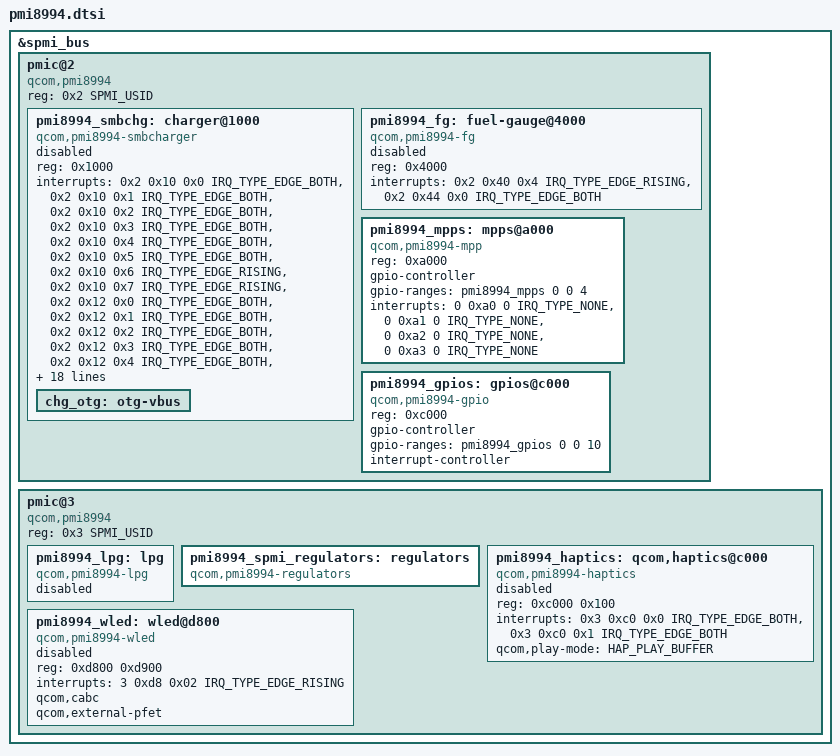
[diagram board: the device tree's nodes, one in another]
// SPDX-License-Identifier: GPL-2.0
#include <dt-bindings/interrupt-controller/irq.h>
#include <dt-bindings/spmi/spmi.h>
#include <dt-bindings/input/qcom,spmi-haptics.h>

&spmi_bus {

	pmic@2 {
		compatible = "qcom,pmi8994", "qcom,spmi-pmic";
		reg = <0x2 SPMI_USID>;
		#address-cells = <1>;
		#size-cells = <0>;

		pmi8994_smbchg: charger@1000 {
			compatible = "qcom,pmi8994-smbcharger";
			reg = <0x1000>;

			interrupts = <0x2 0x10 0x0 IRQ_TYPE_EDGE_BOTH>,
				     <0x2 0x10 0x1 IRQ_TYPE_EDGE_BOTH>,
				     <0x2 0x10 0x2 IRQ_TYPE_EDGE_BOTH>,
				     <0x2 0x10 0x3 IRQ_TYPE_EDGE_BOTH>,
				     <0x2 0x10 0x4 IRQ_TYPE_EDGE_BOTH>,
				     <0x2 0x10 0x5 IRQ_TYPE_EDGE_BOTH>,
				     <0x2 0x10 0x6 IRQ_TYPE_EDGE_RISING>,
				     <0x2 0x10 0x7 IRQ_TYPE_EDGE_RISING>,
				     <0x2 0x12 0x0 IRQ_TYPE_EDGE_BOTH>,
				     <0x2 0x12 0x1 IRQ_TYPE_EDGE_BOTH>,
				     <0x2 0x12 0x2 IRQ_TYPE_EDGE_BOTH>,
				     <0x2 0x12 0x3 IRQ_TYPE_EDGE_BOTH>,
				     <0x2 0x12 0x4 IRQ_TYPE_EDGE_BOTH>,
				     <0x2 0x12 0x5 IRQ_TYPE_EDGE_BOTH>,
				     <0x2 0x12 0x6 IRQ_TYPE_EDGE_BOTH>,
				     <0x2 0x12 0x7 IRQ_TYPE_EDGE_BOTH>,
				     <0x2 0x13 0x0 IRQ_TYPE_EDGE_BOTH>,
				     <0x2 0x13 0x1 IRQ_TYPE_EDGE_BOTH>,
				     <0x2 0x13 0x2 IRQ_TYPE_EDGE_BOTH>,
				     <0x2 0x13 0x3 IRQ_TYPE_EDGE_BOTH>,
				     <0x2 0x13 0x4 IRQ_TYPE_EDGE_RISING>,
				     <0x2 0x13 0x5 IRQ_TYPE_EDGE_RISING>,
				     <0x2 0x13 0x6 IRQ_TYPE_EDGE_FALLING>,
				     <0x2 0x14 0x0 IRQ_TYPE_EDGE_BOTH>,
				     <0x2 0x14 0x1 IRQ_TYPE_EDGE_BOTH>,
				     <0x2 0x16 0x0 IRQ_TYPE_EDGE_BOTH>,
				     <0x2 0x16 0x1 IRQ_TYPE_EDGE_BOTH>,
				     <0x2 0x16 0x2 IRQ_TYPE_EDGE_BOTH>,
				     <0x2 0x16 0x3 IRQ_TYPE_EDGE_BOTH>,
				     <0x2 0x16 0x4 IRQ_TYPE_EDGE_BOTH>,
				     <0x2 0x16 0x5 IRQ_TYPE_EDGE_BOTH>;
			interrupt-names = "chg-error",
					  "chg-inhibit",
					  "chg-prechg-sft",
					  "chg-complete-chg-sft",
					  "chg-p2f-thr",
					  "chg-rechg-thr",
					  "chg-taper-thr",
					  "chg-tcc-thr",
					  "batt-hot",
					  "batt-warm",
					  "batt-cold",
					  "batt-cool",
					  "batt-ov",
					  "batt-low",
					  "batt-missing",
					  "batt-term-missing",
					  "usbin-uv",
					  "usbin-ov",
					  "usbin-src-det",
					  "otg-fail",
					  "otg-oc",
					  "aicl-done",
					  "usbid-change",
					  "dcin-uv",
					  "dcin-ov",
					  "power-ok",
					  "temp-shutdown",
					  "wdog-timeout",
					  "flash-fail",
					  "otst2",
					  "otst3";

			status = "disabled";

			chg_otg: otg-vbus { };
		};

		pmi8994_fg: fuel-gauge@4000 {
			compatible = "qcom,pmi8994-fg";
			reg = <0x4000>;

			interrupts = <0x2 0x40 0x4 IRQ_TYPE_EDGE_RISING>,
				     <0x2 0x44 0x0 IRQ_TYPE_EDGE_BOTH>;
			interrupt-names = "soc-delta", "mem-avail";

			status = "disabled";
		};

		pmi8994_mpps: mpps@a000 {
			compatible = "qcom,pmi8994-mpp";
			reg = <0xa000>;
			gpio-controller;
			gpio-ranges = <&pmi8994_mpps 0 0 4>;
			#gpio-cells = <2>;
			interrupts = <0 0xa0 0 IRQ_TYPE_NONE>,
				     <0 0xa1 0 IRQ_TYPE_NONE>,
				     <0 0xa2 0 IRQ_TYPE_NONE>,
				     <0 0xa3 0 IRQ_TYPE_NONE>;
		};

		pmi8994_gpios: gpios@c000 {
			compatible = "qcom,pmi8994-gpio", "qcom,spmi-gpio";
			reg = <0xc000>;
			gpio-controller;
			gpio-ranges = <&pmi8994_gpios 0 0 10>;
			#gpio-cells = <2>;
			interrupt-controller;
			#interrupt-cells = <2>;
		};
	};

	pmic@3 {
		compatible = "qcom,pmi8994", "qcom,spmi-pmic";
		reg = <0x3 SPMI_USID>;
		#address-cells = <1>;
		#size-cells = <0>;

		pmi8994_lpg: lpg {
			compatible = "qcom,pmi8994-lpg";

			#address-cells = <1>;
			#size-cells = <0>;
			#pwm-cells = <2>;

			status = "disabled";
		};

		pmi8994_spmi_regulators: regulators {
			compatible = "qcom,pmi8994-regulators";
			#address-cells = <1>;
			#size-cells = <1>;
		};

		pmi8994_haptics: qcom,haptics@c000 {
			compatible = "qcom,pmi8994-haptics", "qcom,spmi-haptics";
			reg = <0xc000 0x100>;

			interrupts = <0x3 0xc0 0x0 IRQ_TYPE_EDGE_BOTH>,
				     <0x3 0xc0 0x1 IRQ_TYPE_EDGE_BOTH>;
			interrupt-names = "short", "play";

			qcom,play-mode = <HAP_PLAY_BUFFER>;

			status = "disabled";
		};

		pmi8994_wled: wled@d800 {
			compatible = "qcom,pmi8994-wled";
			reg = <0xd800 0xd900>;
			interrupts = <3 0xd8 0x02 IRQ_TYPE_EDGE_RISING>;
			interrupt-names = "short";
			qcom,cabc;
			qcom,external-pfet;
			status = "disabled";
		};
	};
};
